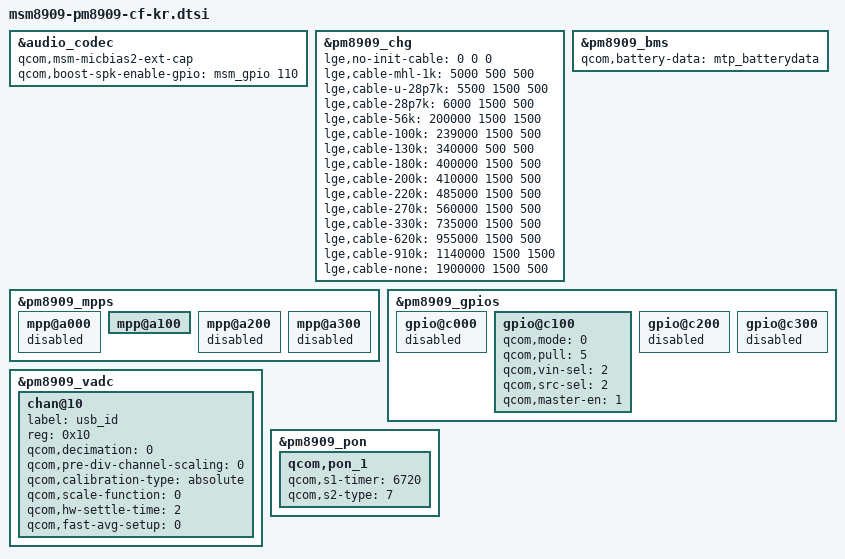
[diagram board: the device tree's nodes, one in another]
/* Copyright (c) 2014, The Linux Foundation. All rights reserved.
 *
 * This program is free software; you can redistribute it and/or modify
 * it under the terms of the GNU General Public License version 2 and
 * only version 2 as published by the Free Software Foundation.
 *
 * This program is distributed in the hope that it will be useful,
 * but WITHOUT ANY WARRANTY; without even the implied warranty of
 * MERCHANTABILITY or FITNESS FOR A PARTICULAR PURPOSE.  See the
 * GNU General Public License for more details.
 */

#include "pm8909-vibrator.dtsi"
#include "pm8909-led.dtsi"

&audio_codec {
	qcom,msm-micbias2-ext-cap;
	qcom,boost-spk-enable-gpio = <&msm_gpio 110 0>;
};

&pm8909_chg {
	status = "ok";

	lge,no-init-cable = <0 0 0>;
	lge,cable-mhl-1k = <5000 500 500>;
	lge,cable-u-28p7k = <5500 1500 500>;
	lge,cable-28p7k = <6000 1500 500>;
	lge,cable-56k = <200000 1500 1500>;
	lge,cable-100k = <239000 1500 500>;
	lge,cable-130k = <340000 500 500>;
	lge,cable-180k = <400000 1500 500>;
	lge,cable-200k = <410000 1500 500>;
	lge,cable-220k = <485000 1500 500>;
	lge,cable-270k = <560000 1500 500>;
	lge,cable-330k = <735000 1500 500>;
	lge,cable-620k = <955000 1500 500>;
	lge,cable-910k = <1140000 1500 1500>;
	lge,cable-none = <1900000 1500  500>;
};

&pm8909_bms {
	status = "ok";
	qcom,battery-data = <&mtp_batterydata>;
};

&pm8909_mpps {
	mpp@a000 { /* MPP 1 */
		/* VDD_PX */
		status = "disabled";
	};

	mpp@a100 { /* MPP 2 */
		/* Backlight PWM */
		status = "ok";
	};

	mpp@a200 { /* MPP 3 */
		/* VREF DAC */
		status = "disabled";
	};

	mpp@a300 { /* MPP 4 */
		/* HR LED */
		status = "disabled";
	};
};

&pm8909_gpios {
	gpio@c000 { /* GPIO 1 */
		/* Battery UICC Alarm */
		status = "disabled";
	};

	gpio@c100 { /* GPIO 2 */
		/* NFC_CLK_REQ */
		qcom,mode = <0>; /* QPNP_PIN_MODE_DIG_IN */
		qcom,pull = <5>; /* QPNP_PIN_PULL_NO */
		qcom,vin-sel = <2>; /* QPNP_PIN_VIN2 */
		qcom,src-sel = <2>; /* QPNP_PIN_SEL_FUNC_1 */
		qcom,master-en = <1>;
	};

	gpio@c200 { /* GPIO 3 */
		/* External regulator control for WTR */
		status = "disabled";
	};

	gpio@c300 { /* GPIO 4 */
		/* External regulator control for APC */
		status = "disabled";
	};
};

&pm8909_vadc {
	chan@10 {
		label = "usb_id";
		reg = <0x10>;
		qcom,decimation = <0>;
		qcom,pre-div-channel-scaling = <0>;
		qcom,calibration-type = "absolute";
		qcom,scale-function = <0>;
		qcom,hw-settle-time = <2>;
		qcom,fast-avg-setup = <0>;
	};
};

&pm8909_pon {
	qcom,pon_1 {
		qcom,s1-timer = <6720>;
		qcom,s2-type = <7>;
	};
};
